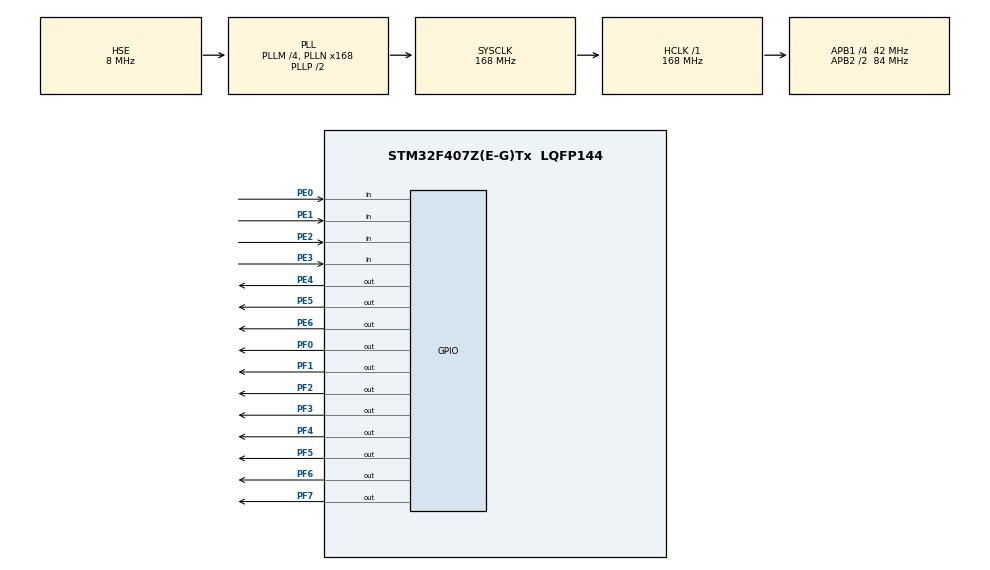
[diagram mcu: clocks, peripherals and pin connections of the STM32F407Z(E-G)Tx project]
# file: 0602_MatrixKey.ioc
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Mcu.Family=STM32F4
Mcu.Name=STM32F407Z(E-G)Tx
Mcu.Package=LQFP144
NVIC.PriorityGroup=NVIC_PRIORITYGROUP_4
PA13.Mode=Serial_Wire
PA13.Signal=SYS_JTMS-SWDIO
PA14.Mode=Serial_Wire
PA14.Signal=SYS_JTCK-SWCLK
PE0.GPIO_PuPd=GPIO_PULLUP
PE0.Signal=GPIO_Input
PE1.GPIO_PuPd=GPIO_PULLUP
PE1.Signal=GPIO_Input
PE2.GPIO_PuPd=GPIO_PULLUP
PE2.Signal=GPIO_Input
PE3.GPIO_PuPd=GPIO_PULLUP
PE3.Signal=GPIO_Input
PE4.PinState=GPIO_PIN_SET
PE4.Signal=GPIO_Output
PE5.PinState=GPIO_PIN_SET
PE5.Signal=GPIO_Output
PE6.PinState=GPIO_PIN_SET
PE6.Signal=GPIO_Output
PF0.PinState=GPIO_PIN_SET
PF0.Signal=GPIO_Output
PF1.PinState=GPIO_PIN_SET
PF1.Signal=GPIO_Output
PF2.PinState=GPIO_PIN_SET
PF2.Signal=GPIO_Output
PF3.PinState=GPIO_PIN_SET
PF3.Signal=GPIO_Output
PF4.PinState=GPIO_PIN_SET
PF4.Signal=GPIO_Output
PF5.PinState=GPIO_PIN_SET
PF5.Signal=GPIO_Output
PF6.PinState=GPIO_PIN_SET
PF6.Signal=GPIO_Output
PF7.PinState=GPIO_PIN_SET
PF7.Signal=GPIO_Output
PH0-OSC_IN.Mode=HSE-External-Oscillator
PH0-OSC_IN.Signal=RCC_OSC_IN
PH1-OSC_OUT.Mode=HSE-External-Oscillator
PH1-OSC_OUT.Signal=RCC_OSC_OUT
ProjectManager.HeapSize=0x200
ProjectManager.StackSize=0x400
ProjectManager.TargetToolchain=STM32CubeIDE
RCC.48MHZClocksFreq_Value=84000000
RCC.AHBFreq_Value=168000000
RCC.APB1CLKDivider=RCC_HCLK_DIV4
RCC.APB1Freq_Value=42000000
RCC.APB1TimFreq_Value=84000000
RCC.APB2CLKDivider=RCC_HCLK_DIV2
RCC.APB2Freq_Value=84000000
RCC.APB2TimFreq_Value=168000000
RCC.CortexFreq_Value=168000000
RCC.HCLKFreq_Value=168000000
RCC.HSE_VALUE=8000000
RCC.HSI_VALUE=16000000
RCC.LSE_VALUE=32768
RCC.PLLM=4
RCC.PLLN=168
RCC.PLLSourceVirtual=RCC_PLLSOURCE_HSE
RCC.SYSCLKFreq_VALUE=168000000
RCC.SYSCLKSource=RCC_SYSCLKSOURCE_PLLCLK
RCC.VCOOutputFreq_Value=336000000
board=custom

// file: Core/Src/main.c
/* USER CODE BEGIN Header */
/**
  ******************************************************************************
  * @file           : main.c
  * @brief          : Main program body
  ******************************************************************************
  * @attention
  *
  * Copyright (c) 2026 STMicroelectronics.
  * All rights reserved.
  *
  * This software is licensed under terms that can be found in the LICENSE file
  * in the root directory of this software component.
  * If no LICENSE file comes with this software, it is provided AS-IS.
  *
  ******************************************************************************
  */
/* USER CODE END Header */
#include "main.h"
#include "gpio.h"

void SystemClock_Config(void);

/* USER CODE BEGIN 0 */
uint16_t i, KeyVal = 0;   // i：循环扫描变量；KeyVal：存储最终识别的按键值
uint8_t PreLine[3] = {2, 0, 1}; // 行号映射数组，匹配代码的扫描时序
/* USER CODE END 0 */

int main(void)
{

  /* MCU Configuration--------------------------------------------------------*/

  /* Reset of all peripherals, Initializes the Flash interface and the Systick. */
  HAL_Init();

  /* Configure the system clock */
  SystemClock_Config();

  /* Initialize all configured peripherals */
  MX_GPIO_Init();

  /* Infinite loop */
  while (1)
  {

    /* USER CODE BEGIN 3 */
	  // 逐行循环扫描，共3行
	    for(i=0; i<3; i++)
	    {
	      // 1. 读取列线电平（PE0~PE3，对应IDR寄存器低4位），判断是否有按键按下
	      if( (GPIOE->IDR & 0x0F) != 0x0F )
	      {
	        // 2. 软件消抖：延时16ms，过滤机械按键的抖动干扰
	        HAL_Delay(16);
	        // 消抖后再次判断，确认按键真的按下，避免误判
	        if( (GPIOE->IDR & 0x0F) != 0x0F )
	        {
	          // 3. 根据列电平值，判断具体哪一列按下，计算键值
	          switch( GPIOE->IDR & 0x0F )
	          {
	            case 0x0E:  // 0b1110 → PE0为低 → 第1列
	              KeyVal = 4 * PreLine[i] + 1;
	              break;
	            case 0x0D:  // 0b1101 → PE1为低 → 第2列
	              KeyVal = 4 * PreLine[i] + 2;
	              break;
	            case 0x0B:  // 0b1011 → PE2为低 → 第3列
	              KeyVal = 4 * PreLine[i] + 3;
	              break;
	            case 0x07:  // 0b0111 → PE3为低 → 第4列
	              KeyVal = 4 * PreLine[i] + 4;
	              break;
	            default:
	              break;
	          }
	        }
	      }
	      // 4. 拉低下一行，为下一轮循环的列检测做准备
	      GPIOE->ODR = ~( 1 << (i+4) );
	    }

	    // 5. 键值转8421 BCD码，输出到LED显示
	    GPIOF->ODR = ~( (KeyVal/10 << 4) + KeyVal%10 );

  }

}

void SystemClock_Config(void)
{
  RCC_OscInitTypeDef RCC_OscInitStruct = {0};
  RCC_ClkInitTypeDef RCC_ClkInitStruct = {0};

  /** Configure the main internal regulator output voltage
  */
  __HAL_RCC_PWR_CLK_ENABLE();
  __HAL_PWR_VOLTAGESCALING_CONFIG(PWR_REGULATOR_VOLTAGE_SCALE1);

  /** Initializes the RCC Oscillators according to the specified parameters
  * in the RCC_OscInitTypeDef structure.
  */
  RCC_OscInitStruct.OscillatorType = RCC_OSCILLATORTYPE_HSE;
  RCC_OscInitStruct.HSEState = RCC_HSE_ON;
  RCC_OscInitStruct.PLL.PLLState = RCC_PLL_ON;
  RCC_OscInitStruct.PLL.PLLSource = RCC_PLLSOURCE_HSE;
  RCC_OscInitStruct.PLL.PLLM = 4;
  RCC_OscInitStruct.PLL.PLLN = 168;
  RCC_OscInitStruct.PLL.PLLP = RCC_PLLP_DIV2;
  RCC_OscInitStruct.PLL.PLLQ = 4;
  if (HAL_RCC_OscConfig(&RCC_OscInitStruct) != HAL_OK)
  {
    Error_Handler();
  }

  /** Initializes the CPU, AHB and APB buses clocks
  */
  RCC_ClkInitStruct.ClockType = RCC_CLOCKTYPE_HCLK|RCC_CLOCKTYPE_SYSCLK
                              |RCC_CLOCKTYPE_PCLK1|RCC_CLOCKTYPE_PCLK2;
  RCC_ClkInitStruct.SYSCLKSource = RCC_SYSCLKSOURCE_PLLCLK;
  RCC_ClkInitStruct.AHBCLKDivider = RCC_SYSCLK_DIV1;
  RCC_ClkInitStruct.APB1CLKDivider = RCC_HCLK_DIV4;
  RCC_ClkInitStruct.APB2CLKDivider = RCC_HCLK_DIV2;

  if (HAL_RCC_ClockConfig(&RCC_ClkInitStruct, FLASH_LATENCY_5) != HAL_OK)
  {
    Error_Handler();
  }
}

void Error_Handler(void)
{
  __disable_irq();
  while (1)
  {
  }
}
